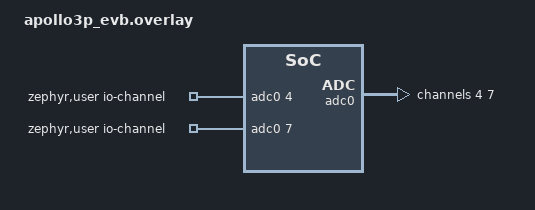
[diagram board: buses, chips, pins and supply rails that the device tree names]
/*
 * Copyright (c) 2024 Ambiq Micro Inc.
 *
 * SPDX-License-Identifier: Apache-2.0
 */
/ {
	zephyr,user {
		io-channels = <&adc0 4>, <&adc0 7>;
	};
};

&adc0 {
	status = "okay";
	#address-cells = <1>;
	#size-cells = <0>;

	channel@4 {
		reg = <4>;
		zephyr,gain = "ADC_GAIN_1";
		zephyr,reference = "ADC_REF_INTERNAL";
		zephyr,acquisition-time = <ADC_ACQ_TIME_DEFAULT>;
		zephyr,resolution = <14>;
	};

	channel@7 {
		reg = <7>;
		zephyr,gain = "ADC_GAIN_1";
		zephyr,reference = "ADC_REF_INTERNAL";
		zephyr,acquisition-time = <ADC_ACQ_TIME_DEFAULT>;
		zephyr,resolution = <12>;
	};
};
